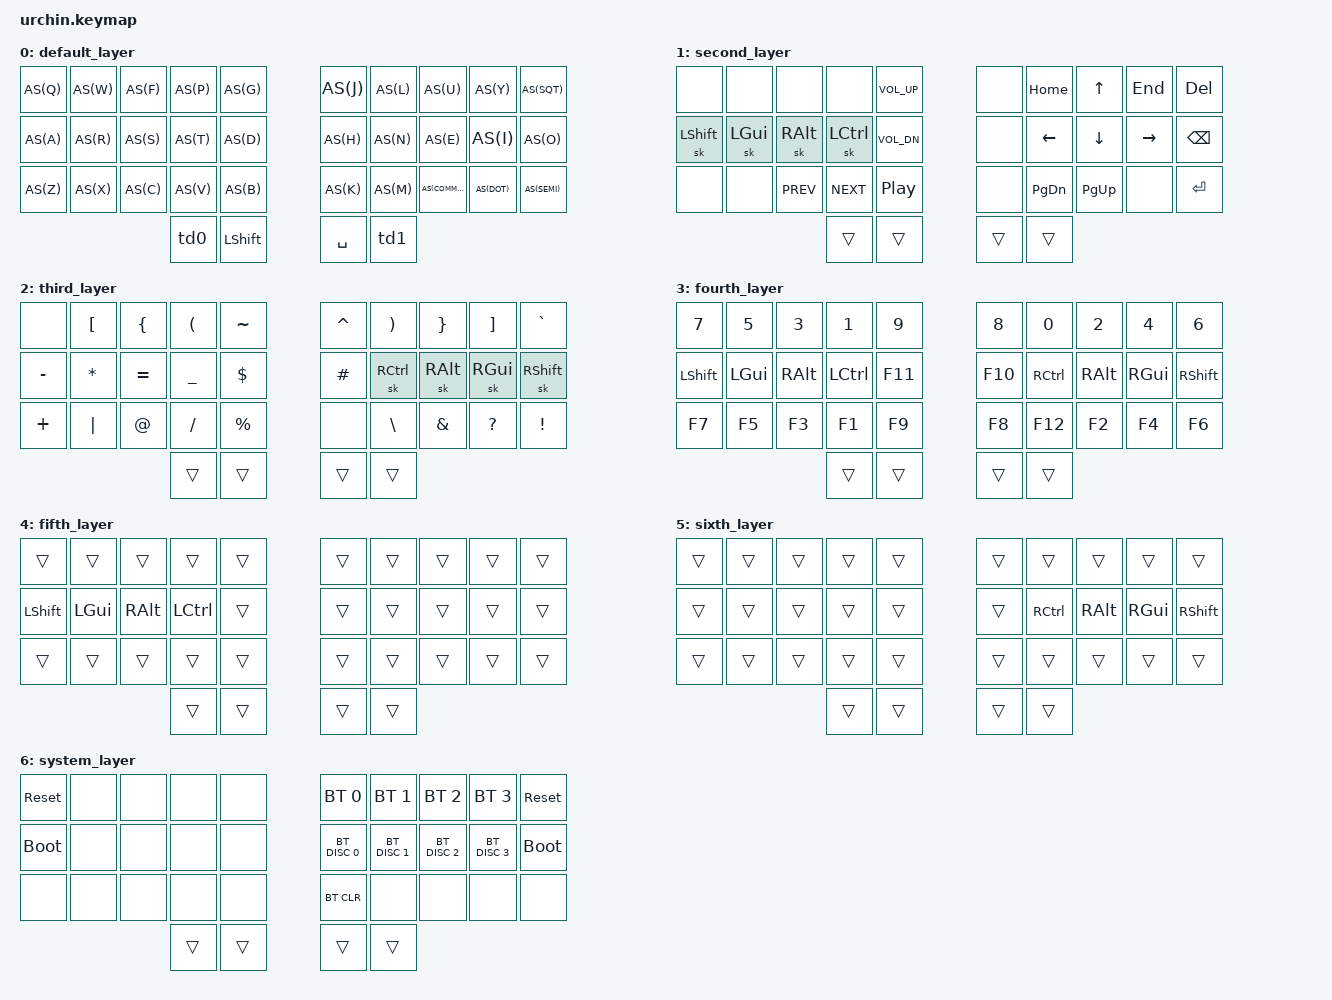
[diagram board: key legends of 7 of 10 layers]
/*
 * Copyright (c) 2020 duckyb
 *
 * SPDX-License-Identifier: MIT
 */

#include <behaviors.dtsi>
#include <dt-bindings/zmk/keys.h>
#include <dt-bindings/zmk/bt.h>
#include <dt-bindings/zmk/outputs.h>

// Layer definitions
#define DEFAULT 0
#define SECOND 	1
#define THIRD 	2
#define FOURTH 	3
#define FIFTH 	4
#define SIXTH 	5
#define SYSTEM 	6
#define MOUSE_KEYS 7
#define MOUSE_TP 8
#define MOUSE_TP_SET 9
// -----------------

#define COMBO(NAME, BINDINGS, KEYPOS, LAYERS) \
  combo_##NAME { \
    timeout-ms = <50>; \
    bindings = <BINDINGS>; \
    key-positions = <KEYPOS>; \
    layers = <LAYERS>; \
  };

&sk {
	// don't release mods on other mods presses
	ignore-modifiers;
};

#define AS(keycode) &as LS(keycode) keycode     // Autoshift Macro


/*
 * Defines to enable/disable features
 *
 * These defines allow us to conditionally enable and disable parts of the keymap config.
 *
 * For example, if we decide to build the firmware without the mouse features, we can
 * disable all the config options that rely on those forks and modules without having
 * to edit the entire keymap file manually every time.
 */

#define HAS_MOUSE_KEYS
#define HAS_MOUSE_TP

#ifdef HAS_MOUSE_KEYS
  #include <dt-bindings/zmk/mouse.h>
  #include <behaviors/mouse_keys.dtsi>
#endif  // HAS_MOUSE_KEYS

#ifdef HAS_MOUSE_TP
  // We store the trackpoint settings in a separate file
  // to make organization a little easier.
  #include "include/mouse_tp.dtsi"
#endif  // HAS_MOUSE_TP



// Adjust layer keys based on enabled features.
//
// This prevents build errors when we build the firmware
// without the mouse keys PR or the TP module.
#ifdef HAS_MOUSE_KEYS
  #define U_THUMB_INNER &mo MOUSE_KEYS
#else
  #define U_THUMB_INNER &none
#endif  // HAS_MOUSE_KEYS

#ifdef HAS_MOUSE_TP
  #define U_TOG_TP_SET &tog MOUSE_TP_SET
#else
  #define U_TOG_TP_SET &none
#endif  // HAS_MOUSE_TP

/ {
	behaviors {
		// Enables holding the first mod-tap key
		// by performing a tap-release-hold sequence.
		// To use it: "&qt KEYCODE1 KEYCODE2"
		qt: quick_tap {
			compatible = "zmk,behavior-hold-tap";
			label = "QUICK_TAP";
			#binding-cells = <2>;
			flavor = "hold-preferred";
			tapping-term-ms = <200>;
			quick-tap-ms = <200>;
			bindings = <&kp>, <&kp>;
		};

		td0: tap_dance_0 {
            compatible = "zmk,behavior-tap-dance";
            #binding-cells = <0>;
            tapping-term-ms = <200>;
            bindings = <&mo SECOND>, <&mo FIFTH>;
        };

		td1: tap_dance_1 {
            compatible = "zmk,behavior-tap-dance";
            #binding-cells = <0>;
            tapping-term-ms = <200>;
            bindings = <&mo THIRD>, <&mo SIXTH>;
        };

        as: auto_shift {
            compatible = "zmk,behavior-hold-tap";
            #binding-cells = <2>;
            tapping_term_ms = <175>;
            quick_tap_ms = <0>;
            flavor = "tap-preferred";
            bindings = <&kp>, <&kp>;
        };
	};

	macros {
		// sometimes my device thinks a modifier is being held down
		// pressing all modifiers fixes it.
		unstick: unstick {
			label = "ZM_unstick";
			compatible = "zmk,behavior-macro";
			#binding-cells = <0>;
			bindings = <&kp LSHIFT &kp RSHIFT &kp LCTRL &kp RCTRL &kp LALT &kp RALT &kp LGUI &kp RGUI>;
		};
	};

	combos {
		compatible = "zmk,combos";

		COMBO(ESC, &kp ESC, 1 2, DEFAULT)
		COMBO(ENTER, &kp ENTER, 17 18, DEFAULT)
		COMBO(BSPC, &kp BSPC, 7 8, DEFAULT)
		COMBO(TAB, &kp TAB, 11 12, DEFAULT)
		COMBO(DEL, &kp DEL, 27 28, DEFAULT)
		COMBO(SYSTEM, &mo SYSTEM, 31 32, DEFAULT)
		COMBO(FOURTH, &mo FOURTH, 30 33, DEFAULT)
		COMBO(BOOTLOADER_LEFT, &bootloader, 0 11 20, DEFAULT)
		COMBO(BOOTLOADER_RIGHT, &bootloader, 10 19 29, DEFAULT)
	};

	keymap {
		compatible = "zmk,keymap";

		default_layer {
			bindings = <
				AS(Q)			AS(W)			AS(F)           AS(P)           AS(G)                    AS(J)           	AS(L)      			AS(U)            AS(Y)			AS(SQT)
				AS(A)			AS(R)			AS(S)     		AS(T)      	  	AS(D)                    AS(H)            	AS(N)           	AS(E)     		 AS(I)			AS(O)
				AS(Z)			AS(X)			AS(C)	        AS(V)           AS(B)               	 AS(K)       		AS(M)          		AS(COMMA)        AS(DOT)		AS(SEMI)
																&td0	     	&kp LSHFT			 	 &kp SPACE	 		&td1
			>;
		};

		second_layer {
			bindings = <
				&none			&none			&none     		&none       	&kp C_VOL_UP            &none          	&kp HOME        &kp UP           &kp END		&kp DEL
				&sk LSHFT		&sk LGUI		&sk RALT        &sk LCTRL       &kp C_VOL_DN            &none           &kp LEFT        &kp DOWN	     &kp RIGHT		&kp BSPC
				&none			&none			&kp C_PREV      &kp C_NEXT      &kp C_PP               	&none       	&kp PG_DN       &kp PG_UP	     &none			&kp ENTER
																&trans       	&trans			        &trans	  		&trans
			>;
		};

		third_layer {
			bindings = <
				&none			&kp LBKT		&kp LBRC         &kp LPAR       &kp TILDE                   &kp CARET       &kp RPAR    	&kp RBRC     	 &kp RBKT			&kp GRAVE
				&kp MINUS		&kp STAR		&kp EQUAL        &kp UNDER      &kp DLLR                    &kp HASH        &sk RCTRL     	&sk RALT    	 &sk RGUI			&sk RSHFT
				&kp PLUS		&kp PIPE		&kp AT           &kp FSLH       &kp PRCNT               	&none       	&kp BSLH	    &kp AMPS	     &kp QMARK			&kp EXCL
																&trans        	&trans		          	 	&trans		    &trans
			>;
		};

		fourth_layer {
			bindings = <
				&kp N7			&kp N5			&kp N3         	&kp N1       	&kp N9                   	&kp N8      	&kp N0  	  	&kp N2    	 	 &kp N4				&kp N6
				&kp LSHFT		&kp LGUI		&kp RALT        &kp LCTRL       &kp F11                     &kp F10         &kp RCTRL     	&kp RALT    	 &kp RGUI			&kp RSHFT
				&kp F7			&kp F5			&kp F3          &kp F1        	&kp F9               		&kp F8       	&kp F12		    &kp F2	    	 &kp F4				&kp F6
														   		&trans        	&trans		          	 	&trans		    &trans
			>;
		};

		fifth_layer {
			bindings = <
				&trans				&trans				&trans            &trans          &trans            	&trans		   	&trans		     &trans		    &trans		&trans
				&kp LSHFT			&kp LGUI 			&kp RALT          &kp LCTRL       &trans                &trans		    &trans		     &trans	 	  	&trans		&trans
				&trans				&trans				&trans            &trans          &trans                &trans	        &trans           &trans   		&trans		&trans
																   		  &trans   		  &trans	     	    &trans	        &trans       	 
			>;
		};

		sixth_layer {
			bindings = <
				&trans				&trans				&trans            &trans          &trans            	&trans		   	&trans		     &trans		    &trans		&trans
				&trans				&trans 				&trans            &trans          &trans                &trans		    &kp RCTRL		 &kp RALT	 	&kp RGUI	&kp RSHFT
				&trans				&trans				&trans            &trans          &trans                &trans	        &trans           &trans   		&trans		&trans
																   		  &trans   		  &trans	     	    &trans	        &trans       	 
			>;
		};

		system_layer {
			bindings = <
				&sys_reset			&none				&none            &none            &none            	   &bt BT_SEL 0   	&bt BT_SEL 1     &bt BT_SEL 2     &bt BT_SEL 3		&sys_reset
				&bootloader			&none				&none            &none            &none                &bt BT_DISC 0    &bt BT_DISC 1    &bt BT_DISC 2    &bt BT_DISC 3		&bootloader
				&none				&none				&none            &none            &none                &bt BT_CLR       &none            &none        	  &none				&none
																   		 &trans   		  &trans	     	   &trans	        &trans       	 
			>;
		};


		#ifdef HAS_MOUSE_KEYS

			MouseKeys_layer {
			display-name = "MouseKeys";
			bindings = <
		// ╭────────────────────────┬────────────────────────┬────────────────────────┬────────────────────────┬────────────────────────┬────────────────────────╮    ╭────────────────────────┬────────────────────────┬────────────────────────┬────────────────────────┬────────────────────────┬────────────────────────╮
			U_TOG_TP_SET             U_TOG_TP_SET             &none                    &mmv MOVE_UP             &msc SCRL_UP             &none                         &none                    &msc SCRL_UP             &mmv MOVE_UP             &none                    U_TOG_TP_SET              U_TOG_TP_SET
		// ├────────────────────────┼────────────────────────┼────────────────────────┼────────────────────────┼────────────────────────┼────────────────────────┤    ├────────────────────────┼────────────────────────┼────────────────────────┼────────────────────────┼────────────────────────┼────────────────────────┤
			&trans                   &none                    &mmv MOVE_LEFT           &mmv MOVE_DOWN           &mmv MOVE_RIGHT          &none                         &none                    &mmv MOVE_LEFT           &mmv MOVE_DOWN           &mmv MOVE_RIGHT          &none                     &trans
		// ├────────────────────────┼────────────────────────┼────────────────────────┼────────────────────────┼────────────────────────┼────────────────────────┤    ├────────────────────────┼────────────────────────┼────────────────────────┼────────────────────────┼────────────────────────┼────────────────────────┤
			&trans                   &none                    &none                    &none                    &msc SCRL_DOWN           &none                         &none                    &msc SCRL_DOWN           &none                    &none                    &trans                    &trans
		// ╰────────────────────────┴────────────────────────┴────────────────────────┴────────────────────────┼────────────────────────┼────────────────────────┤    ├────────────────────────┼────────────────────────┼────────────────────────┼────────────────────────┴────────────────────────┼────────────────────────╯
																								                &mkp LCLK                &mkp RCLK                     &mkp MCLK                &mkp LCLK                
		//                                                                            ╰────────────────────────┴────────────────────────┴────────────────────────╯    ╰────────────────────────┴────────────────────────┴────────────────────────╯
			>;
			};

		#endif

		#ifdef HAS_MOUSE_TP

			// Automatically activated when the mouse or trackpoint moves.
			// Configured in `include/mouse_tp.dtsi`.
			MouseTP_layer {
			display-name = "TP";
			bindings = <
		// ╭────────────────────────┬────────────────────────┬────────────────────────┬────────────────────────┬────────────────────────┬────────────────────────╮    ╭────────────────────────┬────────────────────────┬────────────────────────┬────────────────────────┬────────────────────────┬────────────────────────╮
			U_TOG_TP_SET             U_TOG_TP_SET             &trans                   &trans                   &msc SCRL_UP             &trans                        &trans                   &trans                   &trans                   &trans                   U_TOG_TP_SET              U_TOG_TP_SET
		// ├────────────────────────┼────────────────────────┼────────────────────────┼────────────────────────┼────────────────────────┼────────────────────────┤    ├────────────────────────┼────────────────────────┼────────────────────────┼────────────────────────┼────────────────────────┼────────────────────────┤
			&trans                   &trans                   &trans                   &trans                   &trans                   &trans                        &trans                   &trans                   &trans                   &trans                   &trans                    &trans
		// ├────────────────────────┼────────────────────────┼────────────────────────┼────────────────────────┼────────────────────────┼────────────────────────┤    ├────────────────────────┼────────────────────────┼────────────────────────┼────────────────────────┼────────────────────────┼────────────────────────┤
			&trans                   &trans                   &trans                   &trans                   &msc SCRL_DOWN           &trans                        &trans                   &trans                   &trans                   &trans                   &trans                    &trans
		// ╰────────────────────────┴────────────────────────┴────────────────────────┴────────────────────────┼────────────────────────┼────────────────────────┤    ├────────────────────────┼────────────────────────┼────────────────────────┼────────────────────────┴────────────────────────┼────────────────────────╯
																								                &mkp LCLK                &mkp RCLK                     &mkp MCLK                &mkp LCLK                
		//                                                                            ╰────────────────────────┴────────────────────────┴────────────────────────╯    ╰────────────────────────┴────────────────────────┴────────────────────────╯
			>;
			};

			// You can find the defines for the actual key press behaviors in `include/mouse_tp.dtsi`.
			MouseSettings_layer {
			display-name = "TP Set";
			bindings = <
		// ╭────────────────────────┬────────────────────────┬────────────────────────┬────────────────────────┬────────────────────────┬────────────────────────╮    ╭────────────────────────┬────────────────────────┬────────────────────────┬────────────────────────┬────────────────────────┬────────────────────────╮
			U_TOG_TP_SET             U_TOG_TP_SET             &none                    U_MSS_TP_S_D             U_MSS_TP_S_I             U_MSS_TP_PT_I                 U_MSS_TP_PT_I            U_MSS_TP_S_D             U_MSS_TP_S_I             &none                    U_TOG_TP_SET              U_TOG_TP_SET
		// ├────────────────────────┼────────────────────────┼────────────────────────┼────────────────────────┼────────────────────────┼────────────────────────┤    ├────────────────────────┼────────────────────────┼────────────────────────┼────────────────────────┼────────────────────────┼────────────────────────┤
			U_MSS_RESET              U_MSS_RESET              &none                    U_MSS_TP_NI_D            U_MSS_TP_NI_I            U_MSS_TP_PT_D                 U_MSS_TP_PT_D            U_MSS_TP_NI_D            U_MSS_TP_NI_I            &none                    U_MSS_RESET               U_MSS_RESET
		// ├────────────────────────┼────────────────────────┼────────────────────────┼────────────────────────┼────────────────────────┼────────────────────────┤    ├────────────────────────┼────────────────────────┼────────────────────────┼────────────────────────┼────────────────────────┼────────────────────────┤
			U_MSS_LOG                U_MSS_LOG                &none                    U_MSS_TP_V6_D            U_MSS_TP_V6_I            &none                         &none                    U_MSS_TP_V6_D            U_MSS_TP_V6_I            &none                    U_MSS_LOG                 U_MSS_LOG
		// ╰────────────────────────┴────────────────────────┴────────────────────────┴────────────────────────┼────────────────────────┼────────────────────────┤    ├────────────────────────┼────────────────────────┼────────────────────────┼────────────────────────┴────────────────────────┼────────────────────────╯
																							                    &mkp LCLK                &mkp RCLK                     &none                    &mkp LCLK                
		//                                                                            ╰────────────────────────┴────────────────────────┴────────────────────────╯    ╰────────────────────────┴────────────────────────┴────────────────────────╯
			>;
			};

		#endif

		/* empty_layer {
			bindings = <
				&none				&none				&none            &none            &none            	   &none		   	&none		     &none		    &none		&none
				&none				&none 				&none            &none            &none                &none		    &none		     &none	 	  	&none		&none
				&none				&none				&none            &none            &none                &none	        &none            &none   		&none		&none
																   		 &none   		  &none	     	       &none	        &none       	 
			>;
		}; */
	};
};
